# PY32F030xx register map
Vendor: Puya; Series: PY32F0; File version: 1.0.0
CPU: CM0+ r0p1, little endian, no MPU, no FPU, 4 interrupt priority bits
Registers are 32-bit, read-write, reset 0x0 unless marked. A register's access mark holds for its fields unless they carry their own. Offsets are from the block's base; [hi:lo] are bit positions; lines under a group give offsets from that group; {n}, {i} and the like mark numbered series; 'fields as' and 'values as' point back to an identical list.

## WWDG — Window watchdog
Base 0x40002C00
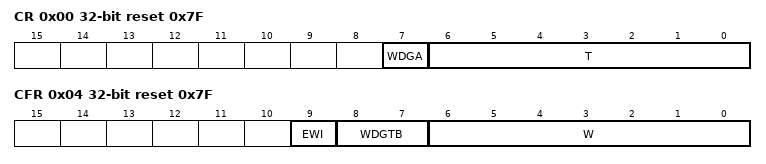
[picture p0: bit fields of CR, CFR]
0x00 CR reset 0x7F — Control register (WWDG_CR)
  [7] WDGA — Activation bit
    0=Disabled (Watchdog disabled); 1=Enabled (Watchdog enabled)
  [6:0] T — 7-bit counter (MSB to LSB)
0x04 CFR reset 0x7F — Configuration register (WWDG_CFR)
  [9] EWI — Early Wakeup Interrupt
    on write: 1=Enable (interrupt occurs whenever the counter reaches the value 0x40)
  [8:7] WDGTB — Timer Base
    0=Div1 (Counter clock (PCLK1 div 4096) div 1); 1=Div2 (Counter clock (PCLK1 div 4096) div 2); 2=Div4 (Counter clock (PCLK1 div 4096) div 4); 3=Div8 (Counter clock (PCLK1 div 4096) div 8)
  [6:0] W — 7-bit window value
0x08 SR — Status register (WWDG_SR)
  [0] EWIF write-0-clears — Early Wakeup Interrupt flag
    on read: 0=Finished (The EWI Interrupt Service Routine has been serviced); 1=Pending (The EWI Interrupt Service Routine has been triggered) | on write: 0=Finished (The EWI Interrupt Service Routine has been serviced)

## DMA — Direct memory access
Base 0x40020000
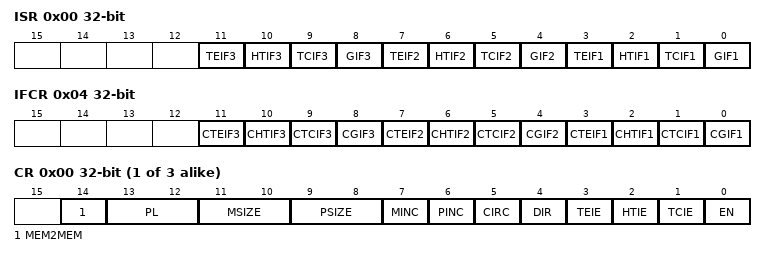
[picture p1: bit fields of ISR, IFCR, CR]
0x00 ISR ro — DMA interrupt status register (DMA_ISR)
  [4n-1] TEIF{n} (n=1..3) — Channel {n} Transfer Error flag
    0=NoError (No transfer error); 1=Error (A transfer error has occured)
  [4n-2] HTIF{n} (n=1..3) — Channel {n} Half Transfer Complete flag
    0=NotHalf (No half transfer event); 1=Half (A half transfer event has occured)
  [4n-3] TCIF{n} (n=1..3) — Channel {n} Transfer Complete flag
    0=NotComplete (No transfer complete event); 1=Complete (A transfer complete event has occured)
  [4n-4] GIF{n} (n=1..3) — Channel {n} Global interrupt flag
    0=NoEvent (No transfer error, half event, complete event); 1=Event (A transfer error, half event or complete event has occured)
0x04 IFCR wo — DMA interrupt flag clear register (DMA_IFCR)
  [4n-1] CTEIF{n} (n=1..3) — Channel {n} Transfer Error clear
    1=Clears the TEIF flag in the ISR register
  [4n-2] CHTIF{n} (n=1..3) — Channel {n} Half Transfer clear
    1=Clears the HTIF flag in the ISR register
  [4n-3] CTCIF{n} (n=1..3) — Channel {n} Transfer Complete clear
    1=Clears the TCIF flag in the ISR register
  [4n-4] CGIF{n} (n=1..3) — Channel {n} Global interrupt clear
    1=Clears the GIF, TEIF, HTIF, TCIF flags in the ISR register
0x08 CH{i} (i=1..3; step 0x14) group — Channel cluster: CCR?, CNDTR?, CPAR?, and CMAR? registers
  0x00 CR — DMA channel configuration register (DMA_CCR)
    [14] MEM2MEM — Memory to memory mode
      0=Disabled (Memory to memory mode disabled); 1=Enabled (Memory to memory mode enabled)
    [13:12] PL — Channel Priority level
      0=Low (Low priority); 1=Medium priority; 2=High priority; 3=Very high priority
    [11:10] MSIZE — Memory size
      0=Bits8 (8-bit size); 1=Bits16 (16-bit size); 2=Bits32 (32-bit size)
    [9:8] PSIZE — Peripheral size
      values as MSIZE
    [7] MINC — Memory increment mode
      0=Disabled (Increment mode disabled); 1=Enabled (Increment mode enabled)
    [6] PINC — Peripheral increment mode
      values as MINC
    [5] CIRC — Circular mode
      0=Disabled (Circular buffer disabled); 1=Enabled (Circular buffer enabled)
    [4] DIR — Data transfer direction
      0=FromPeripheral (Read from peripheral); 1=FromMemory (Read from memory)
    [3] TEIE — Transfer error interrupt enable
      0=Disabled (Transfer Error interrupt disabled); 1=Enabled (Transfer Error interrupt enabled)
    [2] HTIE — Half Transfer interrupt enable
      0=Disabled (Half Transfer interrupt disabled); 1=Enabled (Half Transfer interrupt enabled)
    [1] TCIE — Transfer complete interrupt enable
      0=Disabled (Transfer Complete interrupt disabled); 1=Enabled (Transfer Complete interrupt enabled)
    [0] EN — Channel enable
      0=Disabled (Channel disabled); 1=Enabled (Channel enabled)
  0x04 NDTR — DMA channel 1 number of data register
    [15:0] NDT — Number of data to transfer
  0x08 PAR — DMA channel 1 peripheral address register
    [31:0] PA — Peripheral address
  0x0C MAR — DMA channel 1 memory address register
    [31:0] MA — Memory address
